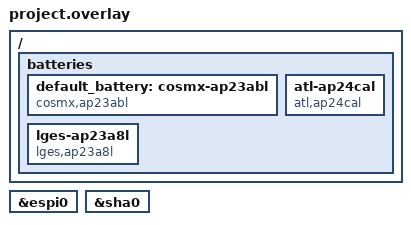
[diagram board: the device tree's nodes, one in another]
/* Copyright 2025 The ChromiumOS Authors
 * Use of this source code is governed by a BSD-style license that can be
 * found in the LICENSE file.
 */

/* kinmen program common DTS includes */

#include <cros/integrated_fwid.dtsi>

/* kinmen project DTS includes */
#include "adc.dtsi"
#include "binman.dtsi"
#include "console.dtsi"
#include "fan.dtsi"
#include "gpios.dtsi"
#include "i2c.dtsi"
#include "interrupts.dtsi"
#include "power_signals.dtsi"
#include "pwm.dtsi"
#include "usb_typec.dtsi"
#include "usba.dtsi"

/ {
	batteries {
		default_battery: cosmx-ap23abl {
			compatible = "cosmx,ap23abl", "battery-smart";
		};
		atl-ap24cal {
			compatible = "atl,ap24cal", "battery-smart";
		};
		lges-ap23a8l {
			compatible = "lges,ap23a8l", "battery-smart";
		};
	};
};

/* AP interface */
&espi0 {
	status = "okay";
};

&sha0 {
	status = "okay";
};
